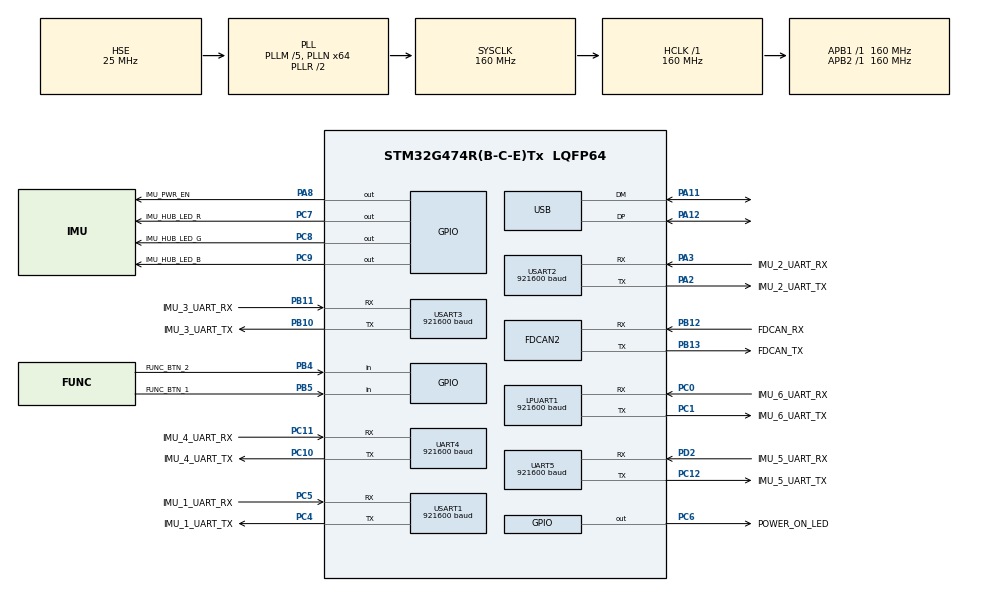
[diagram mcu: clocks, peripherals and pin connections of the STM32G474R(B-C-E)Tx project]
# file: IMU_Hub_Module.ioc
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Dma.LPUART1_RX.5.Direction=DMA_PERIPH_TO_MEMORY
Dma.LPUART1_RX.5.EventEnable=DISABLE
Dma.LPUART1_RX.5.Instance=DMA2_Channel3
Dma.LPUART1_RX.5.MemDataAlignment=DMA_MDATAALIGN_BYTE
Dma.LPUART1_RX.5.MemInc=DMA_MINC_ENABLE
Dma.LPUART1_RX.5.Mode=DMA_CIRCULAR
Dma.LPUART1_RX.5.PeriphDataAlignment=DMA_PDATAALIGN_BYTE
Dma.LPUART1_RX.5.PeriphInc=DMA_PINC_DISABLE
Dma.LPUART1_RX.5.Polarity=HAL_DMAMUX_REQ_GEN_RISING
Dma.LPUART1_RX.5.Priority=DMA_PRIORITY_VERY_HIGH
Dma.LPUART1_RX.5.RequestNumber=1
Dma.LPUART1_RX.5.SignalID=NONE
Dma.LPUART1_RX.5.SyncEnable=DISABLE
Dma.LPUART1_RX.5.SyncPolarity=HAL_DMAMUX_SYNC_NO_EVENT
Dma.LPUART1_RX.5.SyncRequestNumber=1
Dma.LPUART1_RX.5.SyncSignalID=NONE
Dma.Request0=USART1_RX
Dma.Request1=USART2_RX
Dma.Request2=USART3_RX
Dma.Request3=UART4_RX
Dma.Request4=UART5_RX
Dma.Request5=LPUART1_RX
Dma.UART4_RX.3.Direction=DMA_PERIPH_TO_MEMORY
Dma.UART4_RX.3.EventEnable=DISABLE
Dma.UART4_RX.3.Instance=DMA2_Channel1
Dma.UART4_RX.3.MemDataAlignment=DMA_MDATAALIGN_BYTE
Dma.UART4_RX.3.MemInc=DMA_MINC_ENABLE
Dma.UART4_RX.3.Mode=DMA_CIRCULAR
Dma.UART4_RX.3.PeriphDataAlignment=DMA_PDATAALIGN_BYTE
Dma.UART4_RX.3.PeriphInc=DMA_PINC_DISABLE
Dma.UART4_RX.3.Polarity=HAL_DMAMUX_REQ_GEN_RISING
Dma.UART4_RX.3.Priority=DMA_PRIORITY_VERY_HIGH
Dma.UART4_RX.3.RequestNumber=1
Dma.UART4_RX.3.SignalID=NONE
Dma.UART4_RX.3.SyncEnable=DISABLE
Dma.UART4_RX.3.SyncPolarity=HAL_DMAMUX_SYNC_NO_EVENT
Dma.UART4_RX.3.SyncRequestNumber=1
Dma.UART4_RX.3.SyncSignalID=NONE
Dma.UART5_RX.4.Direction=DMA_PERIPH_TO_MEMORY
Dma.UART5_RX.4.EventEnable=DISABLE
Dma.UART5_RX.4.Instance=DMA2_Channel2
Dma.UART5_RX.4.MemDataAlignment=DMA_MDATAALIGN_BYTE
Dma.UART5_RX.4.MemInc=DMA_MINC_ENABLE
Dma.UART5_RX.4.Mode=DMA_CIRCULAR
Dma.UART5_RX.4.PeriphDataAlignment=DMA_PDATAALIGN_BYTE
Dma.UART5_RX.4.PeriphInc=DMA_PINC_DISABLE
Dma.UART5_RX.4.Polarity=HAL_DMAMUX_REQ_GEN_RISING
Dma.UART5_RX.4.Priority=DMA_PRIORITY_VERY_HIGH
Dma.UART5_RX.4.RequestNumber=1
Dma.UART5_RX.4.SignalID=NONE
Dma.UART5_RX.4.SyncEnable=DISABLE
Dma.UART5_RX.4.SyncPolarity=HAL_DMAMUX_SYNC_NO_EVENT
Dma.UART5_RX.4.SyncRequestNumber=1
Dma.UART5_RX.4.SyncSignalID=NONE
Dma.USART1_RX.0.Direction=DMA_PERIPH_TO_MEMORY
Dma.USART1_RX.0.EventEnable=DISABLE
Dma.USART1_RX.0.Instance=DMA1_Channel1
Dma.USART1_RX.0.MemDataAlignment=DMA_MDATAALIGN_BYTE
Dma.USART1_RX.0.MemInc=DMA_MINC_ENABLE
Dma.USART1_RX.0.Mode=DMA_CIRCULAR
Dma.USART1_RX.0.PeriphDataAlignment=DMA_PDATAALIGN_BYTE
Dma.USART1_RX.0.PeriphInc=DMA_PINC_DISABLE
Dma.USART1_RX.0.Polarity=HAL_DMAMUX_REQ_GEN_RISING
Dma.USART1_RX.0.Priority=DMA_PRIORITY_VERY_HIGH
Dma.USART1_RX.0.RequestNumber=1
Dma.USART1_RX.0.SignalID=NONE
Dma.USART1_RX.0.SyncEnable=DISABLE
Dma.USART1_RX.0.SyncPolarity=HAL_DMAMUX_SYNC_NO_EVENT
Dma.USART1_RX.0.SyncRequestNumber=1
Dma.USART1_RX.0.SyncSignalID=NONE
Dma.USART2_RX.1.Direction=DMA_PERIPH_TO_MEMORY
Dma.USART2_RX.1.EventEnable=DISABLE
Dma.USART2_RX.1.Instance=DMA1_Channel2
Dma.USART2_RX.1.MemDataAlignment=DMA_MDATAALIGN_BYTE
Dma.USART2_RX.1.MemInc=DMA_MINC_ENABLE
Dma.USART2_RX.1.Mode=DMA_CIRCULAR
Dma.USART2_RX.1.PeriphDataAlignment=DMA_PDATAALIGN_BYTE
Dma.USART2_RX.1.PeriphInc=DMA_PINC_DISABLE
Dma.USART2_RX.1.Polarity=HAL_DMAMUX_REQ_GEN_RISING
Dma.USART2_RX.1.Priority=DMA_PRIORITY_VERY_HIGH
Dma.USART2_RX.1.RequestNumber=1
Dma.USART2_RX.1.SignalID=NONE
Dma.USART2_RX.1.SyncEnable=DISABLE
Dma.USART2_RX.1.SyncPolarity=HAL_DMAMUX_SYNC_NO_EVENT
Dma.USART2_RX.1.SyncRequestNumber=1
Dma.USART2_RX.1.SyncSignalID=NONE
Dma.USART3_RX.2.Direction=DMA_PERIPH_TO_MEMORY
Dma.USART3_RX.2.EventEnable=DISABLE
Dma.USART3_RX.2.Instance=DMA1_Channel3
Dma.USART3_RX.2.MemDataAlignment=DMA_MDATAALIGN_BYTE
Dma.USART3_RX.2.MemInc=DMA_MINC_ENABLE
Dma.USART3_RX.2.Mode=DMA_CIRCULAR
Dma.USART3_RX.2.PeriphDataAlignment=DMA_PDATAALIGN_BYTE
Dma.USART3_RX.2.PeriphInc=DMA_PINC_DISABLE
Dma.USART3_RX.2.Polarity=HAL_DMAMUX_REQ_GEN_RISING
Dma.USART3_RX.2.Priority=DMA_PRIORITY_VERY_HIGH
Dma.USART3_RX.2.RequestNumber=1
Dma.USART3_RX.2.SignalID=NONE
Dma.USART3_RX.2.SyncEnable=DISABLE
Dma.USART3_RX.2.SyncPolarity=HAL_DMAMUX_SYNC_NO_EVENT
Dma.USART3_RX.2.SyncRequestNumber=1
Dma.USART3_RX.2.SyncSignalID=NONE
FDCAN2.AutoRetransmission=ENABLE
FDCAN2.CalculateBaudRateNominal=1000000
FDCAN2.CalculateTimeBitNominal=1000
FDCAN2.CalculateTimeQuantumNominal=125.0
FDCAN2.DataSyncJumpWidth=4
FDCAN2.DataTimeSeg1=11
FDCAN2.DataTimeSeg2=4
FDCAN2.FrameFormat=FDCAN_FRAME_FD_BRS
FDCAN2.NominalPrescaler=10
FDCAN2.NominalSyncJumpWidth=2
FDCAN2.NominalTimeSeg1=5
FDCAN2.NominalTimeSeg2=2
FDCAN2.StdFiltersNbr=28
FDCAN2.TransmitPause=ENABLE
FDCAN2.TxFifoQueueMode=FDCAN_TX_QUEUE_OPERATION
LPUART1.BaudRate=921600
LPUART1.DMADisableonRxErrorParam=UART_ADVFEATURE_DMA_ENABLEONRXERROR
LPUART1.FIFOMode=UART_FIFOMODE_ENABLE
LPUART1.OverrunDisableParam=UART_ADVFEATURE_OVERRUN_ENABLE
LPUART1.RXFIFOThreshold=UART_RXFIFO_THRESHOLD_1_4
LPUART1.TXFIFOThreshold=UART_TXFIFO_THRESHOLD_1_4
Mcu.Family=STM32G4
Mcu.Name=STM32G474R(B-C-E)Tx
Mcu.Package=LQFP64
NVIC.DMA1_Channel1_IRQn=true\:0\:0\:true\:false\:true\:false\:true\:true
NVIC.DMA1_Channel2_IRQn=true\:0\:0\:true\:false\:true\:false\:true\:true
NVIC.DMA1_Channel3_IRQn=true\:0\:0\:true\:false\:true\:false\:true\:true
NVIC.DMA2_Channel1_IRQn=true\:0\:0\:true\:false\:true\:false\:true\:true
NVIC.DMA2_Channel2_IRQn=true\:0\:0\:true\:false\:true\:false\:true\:true
NVIC.DMA2_Channel3_IRQn=true\:0\:0\:true\:false\:true\:false\:true\:true
NVIC.FDCAN2_IT0_IRQn=true\:2\:0\:true\:false\:true\:true\:true\:true
NVIC.FDCAN2_IT1_IRQn=true\:2\:0\:true\:false\:true\:true\:true\:true
NVIC.LPUART1_IRQn=true\:0\:0\:true\:false\:true\:true\:true\:true
NVIC.PriorityGroup=NVIC_PRIORITYGROUP_4
NVIC.TIM1_UP_TIM16_IRQn=true\:1\:0\:true\:false\:true\:true\:true\:true
NVIC.TIM7_DAC_IRQn=true\:3\:0\:true\:false\:true\:true\:true\:true
NVIC.UART4_IRQn=true\:0\:0\:true\:false\:true\:true\:true\:true
NVIC.UART5_IRQn=true\:0\:0\:true\:false\:true\:true\:true\:true
NVIC.USART1_IRQn=true\:0\:0\:true\:false\:true\:true\:true\:true
NVIC.USART2_IRQn=true\:0\:0\:true\:false\:true\:true\:true\:true
NVIC.USART3_IRQn=true\:0\:0\:true\:false\:true\:true\:true\:true
NVIC.USB_LP_IRQn=true\:4\:0\:true\:false\:true\:false\:true\:true
PA11.Mode=Device
PA11.Signal=USB_DM
PA12.Mode=Device
PA12.Signal=USB_DP
PA13.Mode=Serial_Wire
PA13.Signal=SYS_JTMS-SWDIO
PA14.Mode=Serial_Wire
PA14.Signal=SYS_JTCK-SWCLK
PA2.GPIO_Label=IMU_2_UART_TX
PA2.GPIO_Speed=GPIO_SPEED_FREQ_MEDIUM
PA2.Mode=Asynchronous
PA2.Signal=USART2_TX
PA3.GPIO_Label=IMU_2_UART_RX
PA3.GPIO_Speed=GPIO_SPEED_FREQ_MEDIUM
PA3.Mode=Asynchronous
PA3.Signal=USART2_RX
PA8.GPIO_Label=IMU_PWR_EN
PA8.Signal=GPIO_Output
PB10.GPIO_Label=IMU_3_UART_TX
PB10.GPIO_Speed=GPIO_SPEED_FREQ_MEDIUM
PB10.Mode=Asynchronous
PB10.Signal=USART3_TX
PB11.GPIO_Label=IMU_3_UART_RX
PB11.GPIO_Speed=GPIO_SPEED_FREQ_MEDIUM
PB11.Mode=Asynchronous
PB11.Signal=USART3_RX
PB12.GPIO_Label=FDCAN_RX
PB12.Mode=FDCAN_Activate
PB12.Signal=FDCAN2_RX
PB13.GPIO_Label=FDCAN_TX
PB13.Mode=FDCAN_Activate
PB13.Signal=FDCAN2_TX
PB4.GPIO_Label=FUNC_BTN_2
PB4.Signal=GPIO_Input
PB5.GPIO_Label=FUNC_BTN_1
PB5.Signal=GPIO_Input
PC0.GPIO_Label=IMU_6_UART_RX
PC0.GPIO_Speed=GPIO_SPEED_FREQ_MEDIUM
PC0.Mode=Asynchronous
PC0.Signal=LPUART1_RX
PC1.GPIO_Label=IMU_6_UART_TX
PC1.GPIO_Speed=GPIO_SPEED_FREQ_MEDIUM
PC1.Mode=Asynchronous
PC1.Signal=LPUART1_TX
PC10.GPIO_Label=IMU_4_UART_TX
PC10.GPIO_Speed=GPIO_SPEED_FREQ_MEDIUM
PC10.Mode=Asynchronous
PC10.Signal=UART4_TX
PC11.GPIO_Label=IMU_4_UART_RX
PC11.GPIO_Speed=GPIO_SPEED_FREQ_MEDIUM
PC11.Mode=Asynchronous
PC11.Signal=UART4_RX
PC12.GPIO_Label=IMU_5_UART_TX
PC12.GPIO_Speed=GPIO_SPEED_FREQ_MEDIUM
PC12.Mode=Asynchronous
PC12.Signal=UART5_TX
PC4.GPIO_Label=IMU_1_UART_TX
PC4.GPIO_Speed=GPIO_SPEED_FREQ_MEDIUM
PC4.Mode=Asynchronous
PC4.Signal=USART1_TX
PC5.GPIO_Label=IMU_1_UART_RX
PC5.GPIO_Speed=GPIO_SPEED_FREQ_MEDIUM
PC5.Mode=Asynchronous
PC5.Signal=USART1_RX
PC6.GPIO_Label=POWER_ON_LED
PC6.Signal=GPIO_Output
PC7.GPIO_Label=IMU_HUB_LED_R
PC7.Signal=GPIO_Output
PC8.GPIO_Label=IMU_HUB_LED_G
PC8.Signal=GPIO_Output
PC9.GPIO_Label=IMU_HUB_LED_B
PC9.Signal=GPIO_Output
PD2.GPIO_Label=IMU_5_UART_RX
PD2.GPIO_Speed=GPIO_SPEED_FREQ_MEDIUM
PD2.Mode=Asynchronous
PD2.Signal=UART5_RX
PF0-OSC_IN.Mode=HSE-External-Oscillator
PF0-OSC_IN.Signal=RCC_OSC_IN
PF1-OSC_OUT.Mode=HSE-External-Oscillator
PF1-OSC_OUT.Signal=RCC_OSC_OUT
ProjectManager.HeapSize=0x200
ProjectManager.StackSize=0x400
ProjectManager.TargetToolchain=CMake
RCC.ADC12Freq_Value=160000000
RCC.ADC345Freq_Value=160000000
RCC.AHBFreq_Value=160000000
RCC.APB1Freq_Value=160000000
RCC.APB1TimFreq_Value=160000000
RCC.APB2Freq_Value=160000000
RCC.APB2TimFreq_Value=160000000
RCC.CK48CLockSelection=RCC_USBCLKSOURCE_HSI48
RCC.CSICalibrationValue=32
RCC.CortexFreq_Value=160000000
RCC.EXTERNAL_CLOCK_VALUE=12288000
RCC.FDCANCLockSelection=RCC_FDCANCLKSOURCE_PLL
RCC.HCLKFreq_Value=160000000
RCC.HSE_VALUE=25000000
RCC.HSI48_VALUE=48000000
RCC.HSI_VALUE=16000000
RCC.LSE_VALUE=32768
RCC.PLL1_VCI_Range=RCC_PLL1VCIRANGE_2
RCC.PLL1_VCO_SEL=RCC_PLL1VCOWIDE
RCC.PLL2FRACN=0
RCC.PLL2_VCI_Range=RCC_PLL2VCIRANGE_2
RCC.PLL2_VCO_SEL=RCC_PLL2VCOWIDE
RCC.PLL3FRACN=0
RCC.PLL3_VCI_Range=RCC_PLL3VCIRANGE_3
RCC.PLL3_VCO_SEL=RCC_PLL3VCOWIDE
RCC.PLLFRACN=0
RCC.PLLM=RCC_PLLM_DIV5
RCC.PLLN=64
RCC.PLLQ=RCC_PLLQ_DIV4
RCC.PLLSourceVirtual=RCC_PLLSOURCE_HSE
RCC.PWREXT_OverDrive=PWREXT_OverDrive_ACTIVATED
RCC.ProductRev=revV
RCC.RCC_TIM_PRescaler_Selection=RCC_TIMPRES_DESACTIVATED
RCC.SYSCLKFreq_VALUE=160000000
RCC.SYSCLKSource=RCC_SYSCLKSOURCE_PLLCLK
RCC.USBFreq_Value=48000000
RCC.VCOOutputFreq_Value=320000000
TIM16.AutoReloadPreload=TIM_AUTORELOAD_PRELOAD_DISABLE
TIM16.PeriodNoDither=1000-1
TIM16.Prescaler=160-1
TIM7.AutoReloadPreload=TIM_AUTORELOAD_PRELOAD_ENABLE
TIM7.PeriodNoDither=1000-1
TIM7.Prescaler=160-1
UART4.BaudRate=921600
UART4.DMADisableonRxErrorParam=UART_ADVFEATURE_DMA_ENABLEONRXERROR
UART4.FIFOMode=FIFOMODE_ENABLE
UART4.OverrunDisableParam=UART_ADVFEATURE_OVERRUN_ENABLE
UART4.RXFIFOThreshold=RXFIFO_THRESHOLD_1QUARTERFULL
UART4.TXFIFOThreshold=TXFIFO_THRESHOLD_1QUARTERFULL
UART5.BaudRate=921600
UART5.DMADisableonRxErrorParam=UART_ADVFEATURE_DMA_ENABLEONRXERROR
UART5.FIFOMode=FIFOMODE_ENABLE
UART5.OverrunDisableParam=UART_ADVFEATURE_OVERRUN_ENABLE
UART5.RXFIFOThreshold=RXFIFO_THRESHOLD_1QUARTERFULL
UART5.TXFIFOThreshold=TXFIFO_THRESHOLD_1QUARTERFULL
USART1.BaudRate=921600
USART1.DMADisableonRxErrorParam=ADVFEATURE_DMA_ENABLEONRXERROR
USART1.FIFOMode=FIFOMODE_ENABLE
USART1.OverrunDisableParam=ADVFEATURE_OVERRUN_ENABLE
USART1.RXFIFOThreshold=RXFIFO_THRESHOLD_1QUARTERFULL
USART1.TXFIFOThreshold=TXFIFO_THRESHOLD_1QUARTERFULL
USART1.VirtualMode-Asynchronous=VM_ASYNC
USART2.BaudRate=921600
USART2.DMADisableonRxErrorParam=ADVFEATURE_DMA_ENABLEONRXERROR
USART2.FIFOMode=FIFOMODE_ENABLE
USART2.OverrunDisableParam=ADVFEATURE_OVERRUN_ENABLE
USART2.RXFIFOThreshold=RXFIFO_THRESHOLD_1QUARTERFULL
USART2.TXFIFOThreshold=TXFIFO_THRESHOLD_1QUARTERFULL
USART2.VirtualMode-Asynchronous=VM_ASYNC
USART3.BaudRate=921600
USART3.DMADisableonRxErrorParam=ADVFEATURE_DMA_ENABLEONRXERROR
USART3.FIFOMode=FIFOMODE_ENABLE
USART3.OverrunDisableParam=ADVFEATURE_OVERRUN_ENABLE
USART3.RXFIFOThreshold=RXFIFO_THRESHOLD_1QUARTERFULL
USART3.TXFIFOThreshold=TXFIFO_THRESHOLD_1QUARTERFULL
USART3.VirtualMode-Asynchronous=VM_ASYNC
USB_DEVICE.CLASS_NAME_FS=CDC
USB_DEVICE.VirtualMode=Cdc
USB_DEVICE.VirtualModeFS=Cdc_FS
VP_SYS_VS_DBSignals.Mode=DisableDeadBatterySignals
VP_TIM16_VS_ClockSourceINT.Mode=Enable_Timer
VP_TIM7_VS_ClockSourceINT.Mode=Enable_Timer
VP_USB_DEVICE_VS_USB_DEVICE_CDC_FS.Mode=CDC_FS
board=custom

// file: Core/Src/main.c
/* USER CODE BEGIN Header */
/**
  ******************************************************************************
  * @file           : main.c
  * @brief          : Main program body
  ******************************************************************************
  * @attention
  *
  * Copyright (c) 2025 STMicroelectronics.
  * All rights reserved.
  *
  * This software is licensed under terms that can be found in the LICENSE file
  * in the root directory of this software component.
  * If no LICENSE file comes with this software, it is provided AS-IS.
  *
  ******************************************************************************
  */
/* USER CODE END Header */
#include "main.h"
#include "usb_device.h"

/* USER CODE BEGIN Includes */
#include "system_startup.h"
#include "ioif_agrb_tim.h"      /* IOIF_TIM_SetCallback() */
#include "imu_hub_apps.h"       /* ImuHub_Task_Init(), ImuHub_Task_RunLoop() */
#include "imu_sys_service.h"    /* ImuSysService_Init(), ImuSysService_Run() */
#include "xm_drv.h"             /* XM_Drv_ProcessDeferredSdo() — SDO main-loop defer */

/* Timer IDs (system_startup.c에서 정의) */
extern IOIF_TIMx_t g_main_tim_id;
extern IOIF_TIMx_t g_sys_tim_id;
/* USER CODE END Includes */

FDCAN_HandleTypeDef hfdcan2;

UART_HandleTypeDef hlpuart1;
UART_HandleTypeDef huart4;
UART_HandleTypeDef huart5;
UART_HandleTypeDef huart1;
UART_HandleTypeDef huart2;
UART_HandleTypeDef huart3;
DMA_HandleTypeDef hdma_lpuart1_rx;
DMA_HandleTypeDef hdma_uart4_rx;
DMA_HandleTypeDef hdma_uart5_rx;
DMA_HandleTypeDef hdma_usart1_rx;
DMA_HandleTypeDef hdma_usart2_rx;
DMA_HandleTypeDef hdma_usart3_rx;

TIM_HandleTypeDef htim7;
TIM_HandleTypeDef htim16;

void SystemClock_Config(void);
static void MX_GPIO_Init(void);
static void MX_DMA_Init(void);
static void MX_FDCAN2_Init(void);
static void MX_LPUART1_UART_Init(void);
static void MX_UART4_Init(void);
static void MX_UART5_Init(void);
static void MX_USART1_UART_Init(void);
static void MX_USART2_UART_Init(void);
static void MX_USART3_UART_Init(void);
static void MX_TIM16_Init(void);
static void MX_TIM7_Init(void);

int main(void)
{

  /* MCU Configuration--------------------------------------------------------*/

  /* Reset of all peripherals, Initializes the Flash interface and the Systick. */
  HAL_Init();

  /* Configure the system clock */
  SystemClock_Config();

  /* Initialize all configured peripherals */
  MX_GPIO_Init();
  MX_DMA_Init();
  MX_FDCAN2_Init();
  MX_LPUART1_UART_Init();
  MX_UART4_Init();
  MX_UART5_Init();
  MX_USART1_UART_Init();
  MX_USART2_UART_Init();
  MX_USART3_UART_Init();
  MX_TIM16_Init();
  MX_USB_Device_Init();
  MX_TIM7_Init();
  /* USER CODE BEGIN 2 */
  /* ===== Composition Root: System Init → App Init → Callback Inject → Timer Start ===== */
  System_Startup();                                      /* System Layer 초기화 (타이머 미시작) */
  ImuHub_Task_Init();                                    /* App: Control Task 초기화 */
  ImuSysService_Init();                                  /* App: System Service 초기화 */
  IOIF_TIM_SetCallback(g_main_tim_id, ImuHub_Task_RunLoop);      /* App 콜백 주입: TIM16 → 단일 MainTask */
  /* TIM7(System) 콜백 미등록 — ImuSystemTask 는 ImuHub_Task_RunLoop 안으로 fold 되었다.
   * FDCAN Tx single-writer(BareMetal): HB/SDO/TPDO 송신을 모두 TIM16 한 컨텍스트로 통일. */
  System_StartTimers();                                  /* 타이머 시작 (마지막 — ISR 활성화) */
  /* USER CODE END 2 */

  /* Infinite loop */
  while (1)
  {

    /* USER CODE BEGIN 3 */
    /* SDO 처리 (decode + OD write = PDO 매핑 재구성 + 응답 Tx) — thread level.
     * FDCAN Rx ISR 은 defer-ring 적재만 (SM Safety Checklist: "SDO: ISR에서 플래그만").
     * 응답 Tx 는 Timer ISR(단일 writer)가 tx-defer-ring 을 drain 하여 송신. */
    XM_Drv_ProcessDeferredSdo();
  }
  /* USER CODE END 3 */
}

void SystemClock_Config(void)
{
  RCC_OscInitTypeDef RCC_OscInitStruct = {0};
  RCC_ClkInitTypeDef RCC_ClkInitStruct = {0};

  /** Configure the main internal regulator output voltage
  */
  HAL_PWREx_ControlVoltageScaling(PWR_REGULATOR_VOLTAGE_SCALE1_BOOST);

  /** Initializes the RCC Oscillators according to the specified parameters
  * in the RCC_OscInitTypeDef structure.
  */
  RCC_OscInitStruct.OscillatorType = RCC_OSCILLATORTYPE_HSI48|RCC_OSCILLATORTYPE_HSE;
  RCC_OscInitStruct.HSEState = RCC_HSE_ON;
  RCC_OscInitStruct.HSI48State = RCC_HSI48_ON;
  RCC_OscInitStruct.PLL.PLLState = RCC_PLL_ON;
  RCC_OscInitStruct.PLL.PLLSource = RCC_PLLSOURCE_HSE;
  RCC_OscInitStruct.PLL.PLLM = RCC_PLLM_DIV5;
  RCC_OscInitStruct.PLL.PLLN = 64;
  RCC_OscInitStruct.PLL.PLLP = RCC_PLLP_DIV2;
  RCC_OscInitStruct.PLL.PLLQ = RCC_PLLQ_DIV4;
  RCC_OscInitStruct.PLL.PLLR = RCC_PLLR_DIV2;
  if (HAL_RCC_OscConfig(&RCC_OscInitStruct) != HAL_OK)
  {
    Error_Handler();
  }

  /** Initializes the CPU, AHB and APB buses clocks
  */
  RCC_ClkInitStruct.ClockType = RCC_CLOCKTYPE_HCLK|RCC_CLOCKTYPE_SYSCLK
                              |RCC_CLOCKTYPE_PCLK1|RCC_CLOCKTYPE_PCLK2;
  RCC_ClkInitStruct.SYSCLKSource = RCC_SYSCLKSOURCE_PLLCLK;
  RCC_ClkInitStruct.AHBCLKDivider = RCC_SYSCLK_DIV1;
  RCC_ClkInitStruct.APB1CLKDivider = RCC_HCLK_DIV1;
  RCC_ClkInitStruct.APB2CLKDivider = RCC_HCLK_DIV1;

  if (HAL_RCC_ClockConfig(&RCC_ClkInitStruct, FLASH_LATENCY_4) != HAL_OK)
  {
    Error_Handler();
  }
}

static void MX_FDCAN2_Init(void)
{

  hfdcan2.Instance = FDCAN2;
  hfdcan2.Init.ClockDivider = FDCAN_CLOCK_DIV1;
  hfdcan2.Init.FrameFormat = FDCAN_FRAME_FD_BRS;
  hfdcan2.Init.Mode = FDCAN_MODE_NORMAL;
  hfdcan2.Init.AutoRetransmission = ENABLE;
  hfdcan2.Init.TransmitPause = ENABLE;
  hfdcan2.Init.ProtocolException = DISABLE;
  hfdcan2.Init.NominalPrescaler = 10;
  hfdcan2.Init.NominalSyncJumpWidth = 2;
  hfdcan2.Init.NominalTimeSeg1 = 5;
  hfdcan2.Init.NominalTimeSeg2 = 2;
  hfdcan2.Init.DataPrescaler = 1;
  hfdcan2.Init.DataSyncJumpWidth = 4;
  hfdcan2.Init.DataTimeSeg1 = 11;
  hfdcan2.Init.DataTimeSeg2 = 4;
  hfdcan2.Init.StdFiltersNbr = 28;
  hfdcan2.Init.ExtFiltersNbr = 0;
  hfdcan2.Init.TxFifoQueueMode = FDCAN_TX_QUEUE_OPERATION;
  if (HAL_FDCAN_Init(&hfdcan2) != HAL_OK)
  {
    Error_Handler();
  }

}

static void MX_LPUART1_UART_Init(void)
{

  hlpuart1.Instance = LPUART1;
  hlpuart1.Init.BaudRate = 921600;
  hlpuart1.Init.WordLength = UART_WORDLENGTH_8B;
  hlpuart1.Init.StopBits = UART_STOPBITS_1;
  hlpuart1.Init.Parity = UART_PARITY_NONE;
  hlpuart1.Init.Mode = UART_MODE_TX_RX;
  hlpuart1.Init.HwFlowCtl = UART_HWCONTROL_NONE;
  hlpuart1.Init.OneBitSampling = UART_ONE_BIT_SAMPLE_DISABLE;
  hlpuart1.Init.ClockPrescaler = UART_PRESCALER_DIV1;
  hlpuart1.AdvancedInit.AdvFeatureInit = UART_ADVFEATURE_NO_INIT;
  if (HAL_UART_Init(&hlpuart1) != HAL_OK)
  {
    Error_Handler();
  }
  if (HAL_UARTEx_SetTxFifoThreshold(&hlpuart1, UART_TXFIFO_THRESHOLD_1_4) != HAL_OK)
  {
    Error_Handler();
  }
  if (HAL_UARTEx_SetRxFifoThreshold(&hlpuart1, UART_RXFIFO_THRESHOLD_1_4) != HAL_OK)
  {
    Error_Handler();
  }
  if (HAL_UARTEx_EnableFifoMode(&hlpuart1) != HAL_OK)
  {
    Error_Handler();
  }

}

static void MX_UART4_Init(void)
{

  huart4.Instance = UART4;
  huart4.Init.BaudRate = 921600;
  huart4.Init.WordLength = UART_WORDLENGTH_8B;
  huart4.Init.StopBits = UART_STOPBITS_1;
  huart4.Init.Parity = UART_PARITY_NONE;
  huart4.Init.Mode = UART_MODE_TX_RX;
  huart4.Init.HwFlowCtl = UART_HWCONTROL_NONE;
  huart4.Init.OverSampling = UART_OVERSAMPLING_16;
  huart4.Init.OneBitSampling = UART_ONE_BIT_SAMPLE_DISABLE;
  huart4.Init.ClockPrescaler = UART_PRESCALER_DIV1;
  huart4.AdvancedInit.AdvFeatureInit = UART_ADVFEATURE_NO_INIT;
  if (HAL_UART_Init(&huart4) != HAL_OK)
  {
    Error_Handler();
  }
  if (HAL_UARTEx_SetTxFifoThreshold(&huart4, UART_TXFIFO_THRESHOLD_1_4) != HAL_OK)
  {
    Error_Handler();
  }
  if (HAL_UARTEx_SetRxFifoThreshold(&huart4, UART_RXFIFO_THRESHOLD_1_4) != HAL_OK)
  {
    Error_Handler();
  }
  if (HAL_UARTEx_EnableFifoMode(&huart4) != HAL_OK)
  {
    Error_Handler();
  }

}

static void MX_UART5_Init(void)
{

  huart5.Instance = UART5;
  huart5.Init.BaudRate = 921600;
  huart5.Init.WordLength = UART_WORDLENGTH_8B;
  huart5.Init.StopBits = UART_STOPBITS_1;
  huart5.Init.Parity = UART_PARITY_NONE;
  huart5.Init.Mode = UART_MODE_TX_RX;
  huart5.Init.HwFlowCtl = UART_HWCONTROL_NONE;
  huart5.Init.OverSampling = UART_OVERSAMPLING_16;
  huart5.Init.OneBitSampling = UART_ONE_BIT_SAMPLE_DISABLE;
  huart5.Init.ClockPrescaler = UART_PRESCALER_DIV1;
  huart5.AdvancedInit.AdvFeatureInit = UART_ADVFEATURE_NO_INIT;
  if (HAL_UART_Init(&huart5) != HAL_OK)
  {
    Error_Handler();
  }
  if (HAL_UARTEx_SetTxFifoThreshold(&huart5, UART_TXFIFO_THRESHOLD_1_4) != HAL_OK)
  {
    Error_Handler();
  }
  if (HAL_UARTEx_SetRxFifoThreshold(&huart5, UART_RXFIFO_THRESHOLD_1_4) != HAL_OK)
  {
    Error_Handler();
  }
  if (HAL_UARTEx_EnableFifoMode(&huart5) != HAL_OK)
  {
    Error_Handler();
  }

}

static void MX_USART1_UART_Init(void)
{

  huart1.Instance = USART1;
  huart1.Init.BaudRate = 921600;
  huart1.Init.WordLength = UART_WORDLENGTH_8B;
  huart1.Init.StopBits = UART_STOPBITS_1;
  huart1.Init.Parity = UART_PARITY_NONE;
  huart1.Init.Mode = UART_MODE_TX_RX;
  huart1.Init.HwFlowCtl = UART_HWCONTROL_NONE;
  huart1.Init.OverSampling = UART_OVERSAMPLING_16;
  huart1.Init.OneBitSampling = UART_ONE_BIT_SAMPLE_DISABLE;
  huart1.Init.ClockPrescaler = UART_PRESCALER_DIV1;
  huart1.AdvancedInit.AdvFeatureInit = UART_ADVFEATURE_NO_INIT;
  if (HAL_UART_Init(&huart1) != HAL_OK)
  {
    Error_Handler();
  }
  if (HAL_UARTEx_SetTxFifoThreshold(&huart1, UART_TXFIFO_THRESHOLD_1_4) != HAL_OK)
  {
    Error_Handler();
  }
  if (HAL_UARTEx_SetRxFifoThreshold(&huart1, UART_RXFIFO_THRESHOLD_1_4) != HAL_OK)
  {
    Error_Handler();
  }
  if (HAL_UARTEx_EnableFifoMode(&huart1) != HAL_OK)
  {
    Error_Handler();
  }

}

static void MX_USART2_UART_Init(void)
{

  huart2.Instance = USART2;
  huart2.Init.BaudRate = 921600;
  huart2.Init.WordLength = UART_WORDLENGTH_8B;
  huart2.Init.StopBits = UART_STOPBITS_1;
  huart2.Init.Parity = UART_PARITY_NONE;
  huart2.Init.Mode = UART_MODE_TX_RX;
  huart2.Init.HwFlowCtl = UART_HWCONTROL_NONE;
  huart2.Init.OverSampling = UART_OVERSAMPLING_16;
  huart2.Init.OneBitSampling = UART_ONE_BIT_SAMPLE_DISABLE;
  huart2.Init.ClockPrescaler = UART_PRESCALER_DIV1;
  huart2.AdvancedInit.AdvFeatureInit = UART_ADVFEATURE_NO_INIT;
  if (HAL_UART_Init(&huart2) != HAL_OK)
  {
    Error_Handler();
  }
  if (HAL_UARTEx_SetTxFifoThreshold(&huart2, UART_TXFIFO_THRESHOLD_1_4) != HAL_OK)
  {
    Error_Handler();
  }
  if (HAL_UARTEx_SetRxFifoThreshold(&huart2, UART_RXFIFO_THRESHOLD_1_4) != HAL_OK)
  {
    Error_Handler();
  }
  if (HAL_UARTEx_EnableFifoMode(&huart2) != HAL_OK)
  {
    Error_Handler();
  }

}

static void MX_USART3_UART_Init(void)
{

  huart3.Instance = USART3;
  huart3.Init.BaudRate = 921600;
  huart3.Init.WordLength = UART_WORDLENGTH_8B;
  huart3.Init.StopBits = UART_STOPBITS_1;
  huart3.Init.Parity = UART_PARITY_NONE;
  huart3.Init.Mode = UART_MODE_TX_RX;
  huart3.Init.HwFlowCtl = UART_HWCONTROL_NONE;
  huart3.Init.OverSampling = UART_OVERSAMPLING_16;
  huart3.Init.OneBitSampling = UART_ONE_BIT_SAMPLE_DISABLE;
  huart3.Init.ClockPrescaler = UART_PRESCALER_DIV1;
  huart3.AdvancedInit.AdvFeatureInit = UART_ADVFEATURE_NO_INIT;
  if (HAL_UART_Init(&huart3) != HAL_OK)
  {
    Error_Handler();
  }
  if (HAL_UARTEx_SetTxFifoThreshold(&huart3, UART_TXFIFO_THRESHOLD_1_4) != HAL_OK)
  {
    Error_Handler();
  }
  if (HAL_UARTEx_SetRxFifoThreshold(&huart3, UART_RXFIFO_THRESHOLD_1_4) != HAL_OK)
  {
    Error_Handler();
  }
  if (HAL_UARTEx_EnableFifoMode(&huart3) != HAL_OK)
  {
    Error_Handler();
  }

}

static void MX_TIM7_Init(void)
{

  TIM_MasterConfigTypeDef sMasterConfig = {0};

  htim7.Instance = TIM7;
  htim7.Init.Prescaler = 160-1;
  htim7.Init.CounterMode = TIM_COUNTERMODE_UP;
  htim7.Init.Period = 999;
  htim7.Init.AutoReloadPreload = TIM_AUTORELOAD_PRELOAD_ENABLE;
  if (HAL_TIM_Base_Init(&htim7) != HAL_OK)
  {
    Error_Handler();
  }
  sMasterConfig.MasterOutputTrigger = TIM_TRGO_RESET;
  sMasterConfig.MasterSlaveMode = TIM_MASTERSLAVEMODE_DISABLE;
  if (HAL_TIMEx_MasterConfigSynchronization(&htim7, &sMasterConfig) != HAL_OK)
  {
    Error_Handler();
  }

}

static void MX_TIM16_Init(void)
{

  htim16.Instance = TIM16;
  htim16.Init.Prescaler = 160-1;
  htim16.Init.CounterMode = TIM_COUNTERMODE_UP;
  htim16.Init.Period = 999;
  htim16.Init.ClockDivision = TIM_CLOCKDIVISION_DIV1;
  htim16.Init.RepetitionCounter = 0;
  htim16.Init.AutoReloadPreload = TIM_AUTORELOAD_PRELOAD_DISABLE;
  if (HAL_TIM_Base_Init(&htim16) != HAL_OK)
  {
    Error_Handler();
  }

}

static void MX_DMA_Init(void)
{

  /* DMA controller clock enable */
  __HAL_RCC_DMAMUX1_CLK_ENABLE();
  __HAL_RCC_DMA1_CLK_ENABLE();
  __HAL_RCC_DMA2_CLK_ENABLE();

  /* DMA interrupt init */
  /* DMA1_Channel1_IRQn interrupt configuration */
  HAL_NVIC_SetPriority(DMA1_Channel1_IRQn, 0, 0);
  HAL_NVIC_EnableIRQ(DMA1_Channel1_IRQn);
  /* DMA1_Channel2_IRQn interrupt configuration */
  HAL_NVIC_SetPriority(DMA1_Channel2_IRQn, 0, 0);
  HAL_NVIC_EnableIRQ(DMA1_Channel2_IRQn);
  /* DMA1_Channel3_IRQn interrupt configuration */
  HAL_NVIC_SetPriority(DMA1_Channel3_IRQn, 0, 0);
  HAL_NVIC_EnableIRQ(DMA1_Channel3_IRQn);
  /* DMA2_Channel1_IRQn interrupt configuration */
  HAL_NVIC_SetPriority(DMA2_Channel1_IRQn, 0, 0);
  HAL_NVIC_EnableIRQ(DMA2_Channel1_IRQn);
  /* DMA2_Channel2_IRQn interrupt configuration */
  HAL_NVIC_SetPriority(DMA2_Channel2_IRQn, 0, 0);
  HAL_NVIC_EnableIRQ(DMA2_Channel2_IRQn);
  /* DMA2_Channel3_IRQn interrupt configuration */
  HAL_NVIC_SetPriority(DMA2_Channel3_IRQn, 0, 0);
  HAL_NVIC_EnableIRQ(DMA2_Channel3_IRQn);

}

static void MX_GPIO_Init(void)
{
  GPIO_InitTypeDef GPIO_InitStruct = {0};

  /* GPIO Ports Clock Enable */
  __HAL_RCC_GPIOF_CLK_ENABLE();
  __HAL_RCC_GPIOC_CLK_ENABLE();
  __HAL_RCC_GPIOA_CLK_ENABLE();
  __HAL_RCC_GPIOB_CLK_ENABLE();
  __HAL_RCC_GPIOD_CLK_ENABLE();

  /*Configure GPIO pin Output Level */
  HAL_GPIO_WritePin(GPIOC, POWER_ON_LED_Pin|IMU_HUB_LED_R_Pin|IMU_HUB_LED_G_Pin|IMU_HUB_LED_B_Pin, GPIO_PIN_RESET);

  /*Configure GPIO pin Output Level */
  HAL_GPIO_WritePin(IMU_PWR_EN_GPIO_Port, IMU_PWR_EN_Pin, GPIO_PIN_RESET);

  /*Configure GPIO pins : POWER_ON_LED_Pin IMU_HUB_LED_R_Pin IMU_HUB_LED_G_Pin IMU_HUB_LED_B_Pin */
  GPIO_InitStruct.Pin = POWER_ON_LED_Pin|IMU_HUB_LED_R_Pin|IMU_HUB_LED_G_Pin|IMU_HUB_LED_B_Pin;
  GPIO_InitStruct.Mode = GPIO_MODE_OUTPUT_PP;
  GPIO_InitStruct.Pull = GPIO_NOPULL;
  GPIO_InitStruct.Speed = GPIO_SPEED_FREQ_LOW;
  HAL_GPIO_Init(GPIOC, &GPIO_InitStruct);

  /*Configure GPIO pin : IMU_PWR_EN_Pin */
  GPIO_InitStruct.Pin = IMU_PWR_EN_Pin;
  GPIO_InitStruct.Mode = GPIO_MODE_OUTPUT_PP;
  GPIO_InitStruct.Pull = GPIO_NOPULL;
  GPIO_InitStruct.Speed = GPIO_SPEED_FREQ_LOW;
  HAL_GPIO_Init(IMU_PWR_EN_GPIO_Port, &GPIO_InitStruct);

  /*Configure GPIO pins : FUNC_BTN_2_Pin FUNC_BTN_1_Pin */
  GPIO_InitStruct.Pin = FUNC_BTN_2_Pin|FUNC_BTN_1_Pin;
  GPIO_InitStruct.Mode = GPIO_MODE_INPUT;
  GPIO_InitStruct.Pull = GPIO_NOPULL;
  HAL_GPIO_Init(GPIOB, &GPIO_InitStruct);

}

void Error_Handler(void)
{
  __disable_irq();
  while (1)
  {
  }
}
